# ExynosT100 register map
Vendor: SAMSUNG System LSI; Series: ARMCM4F; File version: 0.1
CPU: CM4 r1p0, little endian, MPU, FPU, 3 interrupt priority bits
Registers are 32-bit, read-write, reset 0x0 unless marked. A register's access mark holds for its fields unless they carry their own. Offsets are from the block's base; lines under a group give offsets from that group; [hi:lo] are bit positions; {n}, {i} and the like mark numbered series; 'fields as' and 'values as' point back to an identical list; <NAME> marks a mode.

## Memory map
0x40001000 NORREG size 0x100 — NOR Control
0x40002000 DMAC size 0x1F4 — Direct Memory Access Controller Common
0x40010000 CRC size 0x60 — CRC Calculators
0x40020000 USIB size 0x80
0x40021000 I2CB0 size 0x80
0x40021400 I2CB1 size 0x80
0x40022000 UART0 size 0x80
0x40022400 UART1 size 0x80
0x40023000 GPIO size 0x130 — General-Purpose Input Output
0x40024000 QSPI size 0x130 — Flash controller
0x40080000 CMU size 0x100 — Clock management
0x40080800 PMU size 0x90 — Power Management
0x40080C00 RESET size 0x40 — Reset Control
0x400A0000 TMR0 size 0x10 — 16-bit simple timer
0x400A0010 TMR1 size 0x10
0x400A0020 TMR2 size 0x10
0x400A0030 TMR3 size 0x10
0x400A0040 TMR4 size 0x10
0x400A0080 WDT size 0x40 — 20-bit WatchdogTimer
0x400A0400 PWM0 size 0x100 — PWM
0x400A0500 PWM1 size 0x100
0x400A0A00 RTC size 0x100 — Real time clock
0x400A0C00 ADC size 0x100 — Analog to Digiral Convertor
0x400A0F10 DMAC_Peri size 0x10 — Direct Memory Access Controller Common
0x400B0000 PAD size 0xA4 — IO PAD control
0x40100000 AES size 0x100

## Interrupts
0 WKUP (PAD) — Wake-up interrupt
1 POR (RESET) — Reset interrupt
2 WDT — WDT: This interrupt occurs when CNT is matched with DAT
3 RTC_TICK (RTC) — RTC Interrupt
4 RTC_ALARM (RTC) — RTC Interrupt
5 RTC_TICK1 (RTC) — RTC Interrupt
6 TIMER0 (TMR0) — TIMER0: This interrupt occurs when CNT is matched with DAT
7 TIMER1 (TMR1) — TIMER1: This interrupt occurs when CNT is matched with DAT
8 TIMER2 (TMR2) — TIMER2: This interrupt occurs when CNT is matched with DAT
9 TIMER3 (TMR3) — TIMER3: This interrupt occurs when CNT is matched with DAT
10 TIMER4 (TMR4) — TIMER4: This interrupt occurs when CNT is matched with DAT
11 UDS_TICK (PMU)
12 UDS_RTC (PMU)
13 LDOOFF (PMU) — LDOOFF interrupt
14 NOR_COMPLETE (NORREG) — When Erase and Write Operation of NOR Flash was completed
15 FPU (PAD) — FPU interrupt
16 LVD (PMU)
17 ADC — ADC Interrupt
{n+18} DMA{n} (DMAC) (n=0..7) — This interrupt occurs upon the completion of DMA operation or error
26 PWM0 — PWM ch 1
27 PWM1 — PWM ch 2
32 USIB — There are sub-interrupts on SPI Slave interface block
33 I2CB0 — There are sub-interrupts on SPI Slave interface block
34 I2CB1 — There are sub-interrupts on I2C B 1 interface block.
35 UART0 — There are sub-interrupts on SPI Slave interface block
36 UART1 — There are sub-interrupts on UART1 interface block
50 AES — AES operation completion
{n+51} GPIO{n} (GPIO) (n=0..15) — There is interrupts for the GPIO{n}.
{n+51} GPIO{n} (GPIO) (n=16..31) — There are interrupts for the other GPIOs except of GPIO0~15.
83 BOD (PMU)

## DMAC_Peri — Direct Memory Access Controller Common
Base 0x400A0F10
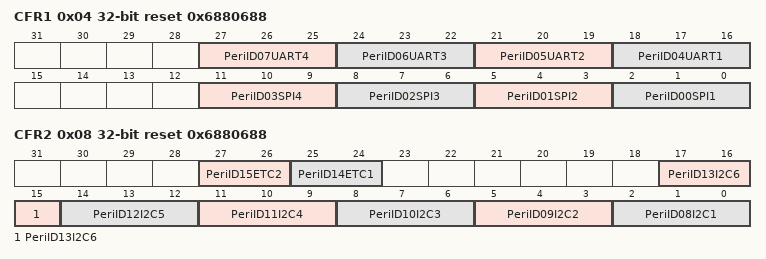
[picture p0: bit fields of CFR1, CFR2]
0x04 CFR1 reset 0x6880688 — DMA Peri-ID(0~7) configuration Register
  [27:25] PeriID07UART4 — Select one peripheral among UART interface group as Peri-ID 7 : 0 = UART0 TX_FIFO 1 = UART0 RX_FIFO 2 = UART1 TX_FIFO 3 = UART1 RX_FIFO (default) 4 = UART2 TX_FIFO 5 = UART2 RX_FIFO
  [24:22] PeriID06UART3 — Select one peripheral among UART interface group as Peri-ID 6 (default) 2 = UART1 TX_FIFO
  [21:19] PeriID05UART2 — Select one peripheral among UART interface group as Peri-ID 5 (default) 1 = UART0 RX_FIFO
  [18:16] PeriID04UART1 — Select one peripheral among UART interface group as Peri-ID 4 (default) 0 = UART0 TX_FIFO
  [11:9] PeriID03SPI4 — Select one peripheral among SPI interface group as Peri-ID 3 : 0 = SPI Slave TX_FIFO 1 = SPI Slave RX_FIFO 2 = SPI Master TX_FIFO 3 = SPI Master RX_FIFO (default) 4 = SPI Both TX_FIFO 5 = SPI Both RX_FIFO
  [8:6] PeriID02SPI3 — Select one peripheral among SPI interface group as Peri-ID 2 (default) 2 = SPI Master TX_FIFO
  [5:3] PeriID01SPI2 — Select one peripheral among SPI interface group as Peri-ID 1 (default) 1 = SPI Slave RX_FIFO
  [2:0] PeriID00SPI1 — Select one peripheral among SPI interface group as Peri-ID 0 (default) 0 = SPI Slave TX_FIFO
0x08 CFR2 reset 0x6880688 — DMA Peri-ID(0~7) configuration Register
  [27:26] PeriID15ETC2 — Select one peripheral among GTimer & ADC interface group as Peri-ID 15 : 0 = General Timer 0 1 = General Timer 1 2 = General Timer 2 3 = ADC (default)
  [25:24] PeriID14ETC1 — Select one peripheral among GTimer & ADC interface group as Peri-ID 14 (default) 1 = general timer 1
  [17:15] PeriID13I2C6 — Select one peripheral among I2C interface group as Peri-ID 13 : 0 = I2C Slave TX_FIFO 1 = I2C Slave RX_FIFO 2 = I2C Master 0 TX_FIFO 3 = I2C Master 0 RX_FIFO 4 = I2C Master 1 TX_FIFO 5 = I2C Master 1 RX_FIFO (default) 6 = I2C Both TX_FIFO 7 = I2C Both RX_FIFO
  [14:12] PeriID12I2C5 — Select one peripheral among I2C interface group as Peri-ID 12 (default) 4 = I2C Master 1 TX_FIFO
  [11:9] PeriID11I2C4 — Select one peripheral among I2C interface group as Peri-ID 11 (default) 3 = I2C Master 0 RX_FIFO
  [8:6] PeriID10I2C3 — Select one peripheral among I2C interface group as Peri-ID 10 (default) 2 = I2C Master 0 TX_FIFO
  [5:3] PeriID09I2C2 — Select one peripheral among I2C interface group as Peri-ID 9 (default) 1 = I2C Slave RX_FIFO
  [2:0] PeriID08I2C1 — Select one peripheral among I2C interface group as Peri-ID 8 (default) 0 = I2C Slave TX_FIFO

## Licence text in the file
ARM Limited (ARM) is supplying this software for use with Cortex-M processor based microcontroller, but can be equally used for other suitable processor architectures. This file can be freely distributed. Modifications to this file shall be clearly marked. . THIS SOFTWARE IS PROVIDED "AS IS". NO WARRANTIES, WHETHER EXPRESS, IMPLIED. OR STATUTORY, INCLUDING, BUT NOT LIMITED TO, IMPLIED WARRANTIES OF. MERCHANTABILITY AND FITNESS FOR A PARTICULAR PURPOSE APPLY TO THIS SOFTWARE. ARM SHALL NOT, IN ANY CIRCUMSTANCES, BE LIABLE FOR SPECIAL, INCIDENTAL, OR. CONSEQUENTIAL DAMAGES, FOR ANY REASON WHATSOEVER.

## Notices in the file
Copyright (C) 2012 ARM Limited. All rights reserved.
